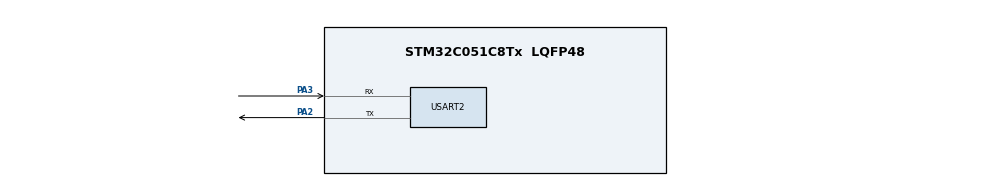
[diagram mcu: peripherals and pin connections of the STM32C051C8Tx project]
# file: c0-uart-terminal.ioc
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Mcu.Family=STM32C0
Mcu.Name=STM32C051C8Tx
Mcu.Package=LQFP48
NVIC.USART2_IRQn=true\:0\:0\:false\:false\:true\:true\:true\:true
PA2.Mode=Asynchronous
PA2.Signal=USART2_TX
PA3.Mode=Asynchronous
PA3.Signal=USART2_RX
ProjectManager.HeapSize=0x200
ProjectManager.StackSize=0x400
ProjectManager.TargetToolchain=STM32CubeIDE
RCC.ADCFreq_Value=12000000
RCC.AHBFreq_Value=12000000
RCC.CortexFreq_Value=12000000
RCC.EXTERNAL_CLOCK_VALUE=12288000
RCC.HCLKFreq_Value=12000000
RCC.HSE_VALUE=8000000
RCC.HSI_VALUE=48000000
RCC.LSE_VALUE=32768
RCC.SYSCLKFreq_VALUE=12000000
USART2.VirtualMode-Asynchronous=VM_ASYNC
board=custom

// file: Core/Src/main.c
/* USER CODE BEGIN Header */
/**
  ******************************************************************************
  * @file           : main.c
  * @brief          : Main program body
  ******************************************************************************
  * @attention
  *
  * Copyright (c) 2025 STMicroelectronics.
  * All rights reserved.
  *
  * This software is licensed under terms that can be found in the LICENSE file
  * in the root directory of this software component.
  * If no LICENSE file comes with this software, it is provided AS-IS.
  *
  ******************************************************************************
  */
/* USER CODE END Header */
#include "main.h"

/* USER CODE BEGIN Includes */
#include <stdio.h>
#include <string.h>
/* USER CODE END Includes */

UART_HandleTypeDef huart2;

/* USER CODE BEGIN PV */
#define CMD_BUFFER_SIZE 64
uint8_t rx_char;
char cmd_buffer[CMD_BUFFER_SIZE];
uint8_t cmd_index = 0;
/* USER CODE END PV */

void SystemClock_Config(void);
static void MX_GPIO_Init(void);
static void MX_USART2_UART_Init(void);

/* USER CODE BEGIN 0 */
void process_command(const char *cmd)
{
  if (strncmp(cmd, "read ", 5) == 0)
  {
    uint32_t addr = 0;
    if (sscanf(cmd + 5, "%lx", &addr) == 1)
    {
      volatile uint32_t *reg_ptr = (volatile uint32_t *)addr;
      uint32_t val = *reg_ptr;

      char response[64];
      int len = snprintf(response, sizeof(response), "0x%08lX\r\n", val);
      HAL_UART_Transmit(&huart2, (uint8_t *)response, len, HAL_MAX_DELAY);
    }
    else
    {
      const char *err = "Invalid address format\r\n";
      HAL_UART_Transmit(&huart2, (uint8_t *)err, strlen(err), HAL_MAX_DELAY);
    }
  }
  else
  {
    const char *err = "Unknown command\r\n";
    HAL_UART_Transmit(&huart2, (uint8_t *)err, strlen(err), HAL_MAX_DELAY);
  }
}

void HAL_UART_RxCpltCallback(UART_HandleTypeDef *huart)
{
  if (huart->Instance == USART2)
  {
    // Handle incoming character
    if (rx_char == '\r' || rx_char == '\n')
    {
      // Null-terminate string
      cmd_buffer[cmd_index] = '\0';
      if (cmd_index > 0)
      {
        process_command(cmd_buffer);
      }
      // Reset buffer
      cmd_index = 0;
    }
    else
    {
      if (cmd_index < CMD_BUFFER_SIZE - 1)
      {
        cmd_buffer[cmd_index++] = rx_char;
      }
    }

    // Restart UART receive interrupt for next char
    HAL_UART_Receive_IT(&huart2, &rx_char, 1);
  }
}
/* USER CODE END 0 */

int main(void)
{

  /* MCU Configuration--------------------------------------------------------*/

  /* Reset of all peripherals, Initializes the Flash interface and the Systick. */
  HAL_Init();

  /* Configure the system clock */
  SystemClock_Config();

  /* Initialize all configured peripherals */
  MX_GPIO_Init();
  MX_USART2_UART_Init();

  /* Infinite loop */
  /* USER CODE BEGIN WHILE */
  HAL_UART_Receive_IT(&huart2, &rx_char, 1);
  while (1)
  {
    /* USER CODE END WHILE */

  }
}

void SystemClock_Config(void)
{
  RCC_OscInitTypeDef RCC_OscInitStruct = {0};
  RCC_ClkInitTypeDef RCC_ClkInitStruct = {0};

  __HAL_FLASH_SET_LATENCY(FLASH_LATENCY_0);

  /** Initializes the RCC Oscillators according to the specified parameters
  * in the RCC_OscInitTypeDef structure.
  */
  RCC_OscInitStruct.OscillatorType = RCC_OSCILLATORTYPE_HSI;
  RCC_OscInitStruct.HSIState = RCC_HSI_ON;
  RCC_OscInitStruct.HSIDiv = RCC_HSI_DIV4;
  RCC_OscInitStruct.HSICalibrationValue = RCC_HSICALIBRATION_DEFAULT;
  if (HAL_RCC_OscConfig(&RCC_OscInitStruct) != HAL_OK)
  {
    Error_Handler();
  }

  /** Initializes the CPU, AHB and APB buses clocks
  */
  RCC_ClkInitStruct.ClockType = RCC_CLOCKTYPE_HCLK|RCC_CLOCKTYPE_SYSCLK
                              |RCC_CLOCKTYPE_PCLK1;
  RCC_ClkInitStruct.SYSCLKSource = RCC_SYSCLKSOURCE_HSI;
  RCC_ClkInitStruct.SYSCLKDivider = RCC_SYSCLK_DIV1;
  RCC_ClkInitStruct.AHBCLKDivider = RCC_HCLK_DIV1;
  RCC_ClkInitStruct.APB1CLKDivider = RCC_APB1_DIV1;

  if (HAL_RCC_ClockConfig(&RCC_ClkInitStruct, FLASH_LATENCY_0) != HAL_OK)
  {
    Error_Handler();
  }
}

static void MX_USART2_UART_Init(void)
{

  huart2.Instance = USART2;
  huart2.Init.BaudRate = 115200;
  huart2.Init.WordLength = UART_WORDLENGTH_8B;
  huart2.Init.StopBits = UART_STOPBITS_1;
  huart2.Init.Parity = UART_PARITY_NONE;
  huart2.Init.Mode = UART_MODE_TX_RX;
  huart2.Init.HwFlowCtl = UART_HWCONTROL_NONE;
  huart2.Init.OverSampling = UART_OVERSAMPLING_16;
  huart2.Init.OneBitSampling = UART_ONE_BIT_SAMPLE_DISABLE;
  huart2.Init.ClockPrescaler = UART_PRESCALER_DIV1;
  huart2.AdvancedInit.AdvFeatureInit = UART_ADVFEATURE_NO_INIT;
  if (HAL_UART_Init(&huart2) != HAL_OK)
  {
    Error_Handler();
  }
  if (HAL_UARTEx_SetTxFifoThreshold(&huart2, UART_TXFIFO_THRESHOLD_1_8) != HAL_OK)
  {
    Error_Handler();
  }
  if (HAL_UARTEx_SetRxFifoThreshold(&huart2, UART_RXFIFO_THRESHOLD_1_8) != HAL_OK)
  {
    Error_Handler();
  }
  if (HAL_UARTEx_DisableFifoMode(&huart2) != HAL_OK)
  {
    Error_Handler();
  }

}

static void MX_GPIO_Init(void)
{

  /* GPIO Ports Clock Enable */
  __HAL_RCC_GPIOA_CLK_ENABLE();

}

void Error_Handler(void)
{
  __disable_irq();
  while (1)
  {
  }
}
